# MSP432P401M register map
Vendor: Texas Instruments; File version: 3.230
Registers are 32-bit, read-write, reset 0x0 unless marked. A register's access mark holds for its fields unless they carry their own. Offsets are from the block's base; [hi:lo] are bit positions; {n}, {i} and the like mark numbered series.

## EUSCI_B0
Base 0x40002000
Same registers: EUSCI_B1 0x40002400, EUSCI_B2 0x40002800, EUSCI_B3 0x40002C00
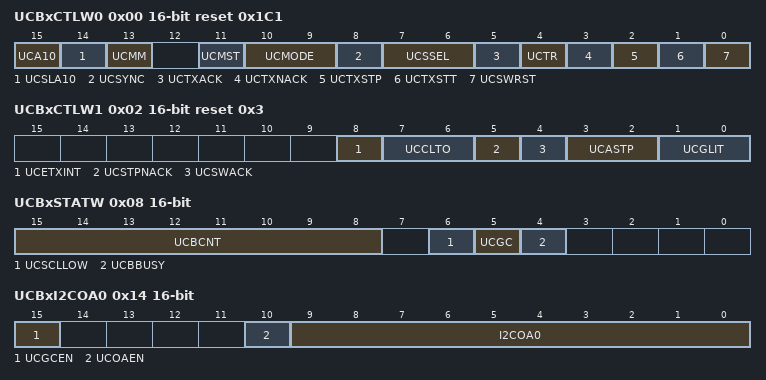
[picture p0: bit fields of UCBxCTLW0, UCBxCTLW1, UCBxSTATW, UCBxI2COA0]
0x00 UCBxCTLW0 16-bit reset 0x1C1 — eUSCI_Bx Control Word Register 0
  [15] UCA10 — Own addressing mode select
    0=Own address is a 7-bit address; 1=Own address is a 10-bit address
  [14] UCSLA10 — Slave addressing mode select
    0=Address slave with 7-bit address; 1=Address slave with 10-bit address
  [13] UCMM — Multi-master environment select
    0=Single master environment. There is no other master in the system. The address compare unit is disabled.; 1=Multi-master environment
  [11] UCMST — Master mode select
    0=Slave mode; 1=Master mode
  [10:9] UCMODE — eUSCI_B mode
    0=3-pin SPI; 1=4-pin SPI (master or slave enabled if STE = 1); 2=4-pin SPI (master or slave enabled if STE = 0); 3=I2C mode
  [8] UCSYNC — Synchronous mode enable
    0=Asynchronous mode; 1=Synchronous mode
  [7:6] UCSSEL — eUSCI_B clock source select
    0=UCLKI; 1=ACLK; 2=SMCLK; 3=SMCLK
  [5] UCTXACK — Transmit ACK condition in slave mode
    0=Do not acknowledge the slave address; 1=Acknowledge the slave address
  [4] UCTR — Transmitter/receiver
    0=Receiver; 1=Transmitter
  [3] UCTXNACK — Transmit a NACK
    0=Acknowledge normally; 1=Generate NACK
  [2] UCTXSTP — Transmit STOP condition in master mode
    0=No STOP generated; 1=Generate STOP
  [1] UCTXSTT — Transmit START condition in master mode
    0=Do not generate START condition; 1=Generate START condition
  [0] UCSWRST — Software reset enable
    0=Disabled. eUSCI_B reset released for operation; 1=Enabled. eUSCI_B logic held in reset state
0x02 UCBxCTLW1 16-bit reset 0x3 — eUSCI_Bx Control Word Register 1
  [8] UCETXINT — Early UCTXIFG0
    0=UCTXIFGx is set after an address match with UCxI2COAx and the direction bit indicating slave transmit; 1=UCTXIFG0 is set for each START condition
  [7:6] UCCLTO — Clock low timeout select
    0=Disable clock low timeout counter; 1=135 000 SYSCLK cycles (approximately 28 ms); 2=150 000 SYSCLK cycles (approximately 31 ms); 3=165 000 SYSCLK cycles (approximately 34 ms)
  [5] UCSTPNACK — ACK all master bytes
    0=Send a non-acknowledge before the STOP condition as a master receiver (conform to I2C standard); 1=All bytes are acknowledged by the eUSCI_B when configured as master receiver
  [4] UCSWACK — SW or HW ACK control
    0=The address acknowledge of the slave is controlled by the eUSCI_B module; 1=The user needs to trigger the sending of the address ACK by issuing UCTXACK
  [3:2] UCASTP — Automatic STOP condition generation
    0=No automatic STOP generation. The STOP condition is generated after the user sets the UCTXSTP bit. The value in UCBxTBCNT is a don't care.; 1=UCBCNTIFG is set with the byte counter reaches the threshold defined in UCBxTBCNT; 2=A STOP condition is generated automatically after the byte counter value reached UCBxTBCNT. UCBCNTIFG is set with the byte counter reaching the threshold
  [1:0] UCGLIT — Deglitch time
    0=50 ns; 1=25 ns; 2=12.5 ns; 3=6.25 ns
0x06 UCBxBRW 16-bit — eUSCI_Bx Baud Rate Control Word Register
  [15:0] UCBR — Bit clock prescaler
0x08 UCBxSTATW 16-bit — eUSCI_Bx Status Register
  [15:8] UCBCNT ro — Hardware byte counter value
  [6] UCSCLLOW ro — SCL low
    on read: 0=SCL is not held low; 1=SCL is held low
  [5] UCGC ro — General call address received
    on read: 0=No general call address received; 1=General call address received
  [4] UCBBUSY ro — Bus busy
    on read: 0=Bus inactive; 1=Bus busy
0x0A UCBxTBCNT 16-bit — eUSCI_Bx Byte Counter Threshold Register
  [7:0] UCTBCNT — Byte counter threshold value
0x0C UCBxRXBUF 16-bit ro — eUSCI_Bx Receive Buffer Register
  [7:0] UCRXBUF — Receive data buffer
0x0E UCBxTXBUF 16-bit — eUSCI_Bx Transmit Buffer Register
  [7:0] UCTXBUF — Transmit data buffer
0x14 UCBxI2COA0 16-bit — eUSCI_Bx I2C Own Address 0 Register
  [15] UCGCEN — General call response enable
    0=Do not respond to a general call; 1=Respond to a general call
  [10] UCOAEN — Own Address enable register
    0=The slave address defined in I2COA0 is disabled; 1=The slave address defined in I2COA0 is enabled
  [9:0] I2COA0 — I2C own address
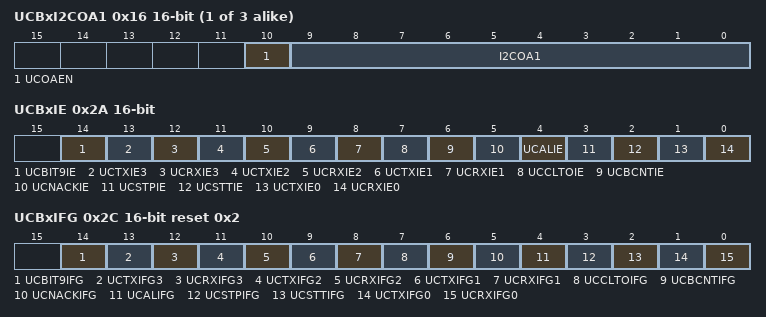
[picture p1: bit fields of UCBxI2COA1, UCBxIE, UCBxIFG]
{0x14+2i} UCBxI2COA{i} 16-bit (i=1..3) — eUSCI_Bx I2C Own Address {i} Register
  [10] UCOAEN — Own Address enable register
    0=The slave address defined in I2COA{i} is disabled; 1=The slave address defined in I2COA{i} is enabled
  [9:0] I2COA{i} — I2C own address
0x1C UCBxADDRX 16-bit ro — eUSCI_Bx I2C Received Address Register
  [9:0] ADDRX — Received Address Register
0x1E UCBxADDMASK 16-bit reset 0x3FF — eUSCI_Bx I2C Address Mask Register
  [9:0] ADDMASK — Address Mask Register. By clearing the corresponding bit of the own address, this bit is a don't care when comparing the address on the bus to the own address. Using this method, it is possible to react on more than one slave address. When all bits of ADDMASKx are set, the address mask feature is deactivated. Modify only when UCSWRST = 1.
0x20 UCBxI2CSA 16-bit — eUSCI_Bx I2C Slave Address Register
  [9:0] I2CSA — I2C slave address
0x2A UCBxIE 16-bit — eUSCI_Bx Interrupt Enable Register
  [all] fields
    0=Interrupt disabled; 1=Interrupt enabled
  [14] UCBIT9IE — Bit position 9 interrupt enable
  [13] UCTXIE3 — Transmit interrupt enable 3
  [12] UCRXIE3 — Receive interrupt enable 3
  [11] UCTXIE2 — Transmit interrupt enable 2
  [10] UCRXIE2 — Receive interrupt enable 2
  [9] UCTXIE1 — Transmit interrupt enable 1
  [8] UCRXIE1 — Receive interrupt enable 1
  [7] UCCLTOIE — Clock low timeout interrupt enable
  [6] UCBCNTIE — Byte counter interrupt enable
  [5] UCNACKIE — Not-acknowledge interrupt enable
  [4] UCALIE — Arbitration lost interrupt enable
  [3] UCSTPIE — STOP condition interrupt enable
  [2] UCSTTIE — START condition interrupt enable
  [1] UCTXIE0 — Transmit interrupt enable 0
  [0] UCRXIE0 — Receive interrupt enable 0
0x2C UCBxIFG 16-bit reset 0x2 — eUSCI_Bx Interrupt Flag Register
  [all] fields
    0=No interrupt pending; 1=Interrupt pending
  [14] UCBIT9IFG — Bit position 9 interrupt flag
  [13] UCTXIFG3 — eUSCI_B transmit interrupt flag 3
  [12] UCRXIFG3 — eUSCI_B receive interrupt flag 3
  [11] UCTXIFG2 — eUSCI_B transmit interrupt flag 2
  [10] UCRXIFG2 — eUSCI_B receive interrupt flag 2
  [9] UCTXIFG1 — eUSCI_B transmit interrupt flag 1
  [8] UCRXIFG1 — eUSCI_B receive interrupt flag 1
  [7] UCCLTOIFG — Clock low timeout interrupt flag
  [6] UCBCNTIFG — Byte counter interrupt flag
  [5] UCNACKIFG — Not-acknowledge received interrupt flag
  [4] UCALIFG — Arbitration lost interrupt flag
  [3] UCSTPIFG — STOP condition interrupt flag
  [2] UCSTTIFG — START condition interrupt flag
  [1] UCTXIFG0 — eUSCI_B transmit interrupt flag 0
  [0] UCRXIFG0 — eUSCI_B receive interrupt flag 0
0x2E UCBxIV 16-bit ro — eUSCI_Bx Interrupt Vector Register
  [15:0] UCIV — eUSCI_B interrupt vector value
    on read: 0=No interrupt pending; 2=Interrupt Source: Arbitration lost; Interrupt Flag: UCALIFG; Interrupt Priority: Highest; 4=Interrupt Source: Not acknowledgment; Interrupt Flag: UCNACKIFG; 6=Interrupt Source: Start condition received; Interrupt Flag: UCSTTIFG; 8=Interrupt Source: Stop condition received; Interrupt Flag: UCSTPIFG; 10=Interrupt Source: Slave 3 Data received; Interrupt Flag: UCRXIFG3; 12=Interrupt Source: Slave 3 Transmit buffer empty; Interrupt Flag: UCTXIFG3; 14=Interrupt Source: Slave 2 Data received; Interrupt Flag: UCRXIFG2; 16=Interrupt Source: Slave 2 Transmit buffer empty; Interrupt Flag: UCTXIFG2; 18=Interrupt Source: Slave 1 Data received; Interrupt Flag: UCRXIFG1; 20=Interrupt Source: Slave 1 Transmit buffer empty; Interrupt Flag: UCTXIFG1; 22=Interrupt Source: Data received; Interrupt Flag: UCRXIFG0; 24=Interrupt Source: Transmit buffer empty; Interrupt Flag: UCTXIFG0; 26=Interrupt Source: Byte counter zero; Interrupt Flag: UCBCNTIFG; 28=Interrupt Source: Clock low timeout; Interrupt Flag: UCCLTOIFG; 30=Interrupt Source: Nineth bit position; Interrupt Flag: UCBIT9IFG; Priority: Lowest

## Notices in the file
Copyright (C) 2012-2018 Texas Instruments Incorporated - http://www.ti.com
Redistribution and use in source and binary forms, with or without
modification, are permitted provided that the following conditions
are met:
Redistributions of source code must retain the above copyright
notice, this list of conditions and the following disclaimer.
Redistributions in binary form must reproduce the above copyright
notice, this list of conditions and the following disclaimer in the
documentation and/or other materials provided with the
distribution.
Neither the name of Texas Instruments Incorporated nor the names of
its contributors may be used to endorse or promote products derived
from this software without specific prior written permission.
THIS SOFTWARE IS PROVIDED BY THE COPYRIGHT HOLDERS AND CONTRIBUTORS
"AS IS" AND ANY EXPRESS OR IMPLIED WARRANTIES, INCLUDING, BUT NOT
LIMITED TO, THE IMPLIED WARRANTIES OF MERCHANTABILITY AND FITNESS FOR
A PARTICULAR PURPOSE ARE DISCLAIMED. IN NO EVENT SHALL THE COPYRIGHT
OWNER OR CONTRIBUTORS BE LIABLE FOR ANY DIRECT, INDIRECT, INCIDENTAL,
SPECIAL, EXEMPLARY, OR CONSEQUENTIAL DAMAGES (INCLUDING, BUT NOT
LIMITED TO, PROCUREMENT OF SUBSTITUTE GOODS OR SERVICES; LOSS OF USE,
DATA, OR PROFITS; OR BUSINESS INTERRUPTION) HOWEVER CAUSED AND ON ANY
THEORY OF LIABILITY, WHETHER IN CONTRACT, STRICT LIABILITY, OR TORT
(INCLUDING NEGLIGENCE OR OTHERWISE) ARISING IN ANY WAY OUT OF THE USE
OF THIS SOFTWARE, EVEN IF ADVISED OF THE POSSIBILITY OF SUCH DAMAGE.
